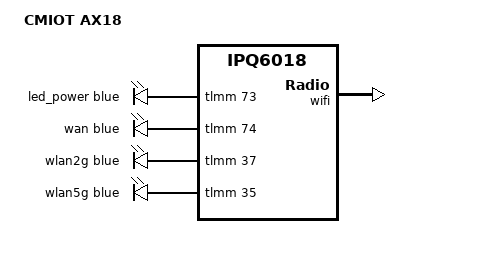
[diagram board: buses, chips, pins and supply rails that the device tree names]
// SPDX-License-Identifier: GPL-2.0-or-later OR MIT

/dts-v1/;

#include "ipq6000-cmiot.dtsi"

/ {
	model = "CMIOT AX18";
	compatible = "cmiot,ax18", "qcom,ipq6018";

	aliases {
		led-boot = &led_power;
		led-failsafe = &led_power;
		led-running = &led_power;
		led-upgrade = &led_power;
	};

	leds {
		compatible = "gpio-leds";

		led_power: power {
			color = <LED_COLOR_ID_BLUE>;
			function = LED_FUNCTION_POWER;
			gpios = <&tlmm 73 GPIO_ACTIVE_HIGH>;
		};

		wan {
			color = <LED_COLOR_ID_BLUE>;
			function = LED_FUNCTION_WAN;
			gpios = <&tlmm 74 GPIO_ACTIVE_HIGH>;
		};

		wlan2g {
			color = <LED_COLOR_ID_BLUE>;
			function = LED_FUNCTION_WLAN_2GHZ;
			gpios = <&tlmm 37 GPIO_ACTIVE_HIGH>;
		};

		wlan5g {
			color = <LED_COLOR_ID_BLUE>;
			function = LED_FUNCTION_WLAN_5GHZ;
			gpios = <&tlmm 35 GPIO_ACTIVE_HIGH>;
		};
	};
};

&wifi {
	status = "okay";
	qcom,ath11k-fw-memory-mode = <1>;
	qcom,ath11k-calibration-variant = "CMIOT-AX18";
};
